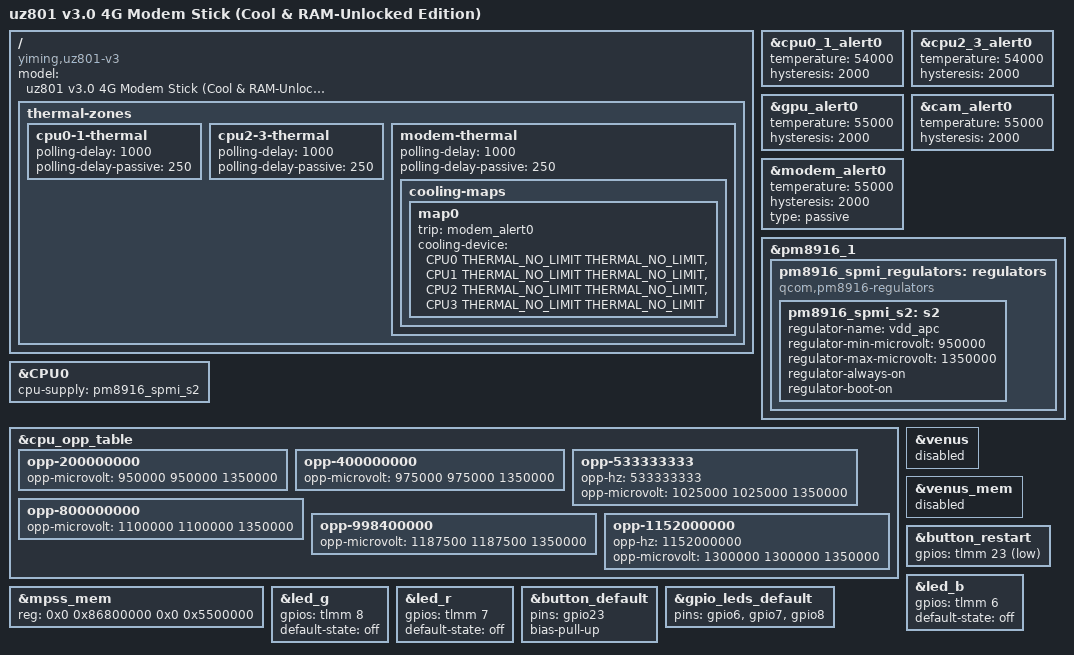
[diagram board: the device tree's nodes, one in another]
// SPDX-License-Identifier: GPL-2.0-only
/*
 * Custom Thermal-Tuned, RAM-Unlocked & OPP-Extended Device Tree
 * for Yiming UZ801 v3.0 (Qualcomm Snapdragon 410 / MSM8916)
 */

/dts-v1/;

#include "msm8916-ufi.dtsi"

/ {
	model = "uz801 v3.0 4G Modem Stick (Cool & RAM-Unlocked Edition)";
	compatible = "yiming,uz801-v3", "qcom,msm8916";

	thermal-zones {
		cpu0-1-thermal {
			polling-delay = <1000>;
			polling-delay-passive = <250>;
		};

		cpu2-3-thermal {
			polling-delay = <1000>;
			polling-delay-passive = <250>;
		};

		modem-thermal {
			polling-delay = <1000>;
			polling-delay-passive = <250>;

			cooling-maps {
				map0 {
					trip = <&modem_alert0>;
					cooling-device = <&CPU0 THERMAL_NO_LIMIT THERMAL_NO_LIMIT>,
							 <&CPU1 THERMAL_NO_LIMIT THERMAL_NO_LIMIT>,
							 <&CPU2 THERMAL_NO_LIMIT THERMAL_NO_LIMIT>,
							 <&CPU3 THERMAL_NO_LIMIT THERMAL_NO_LIMIT>;
				};
			};
		};
	};
};

/* Lower thermal throttling trip points from 75-85C down to 54C to keep chip < 60C */
&cpu0_1_alert0 {
	temperature = <54000>;
	hysteresis = <2000>;
};

&cpu2_3_alert0 {
	temperature = <54000>;
	hysteresis = <2000>;
};

&gpu_alert0 {
	temperature = <55000>;
	hysteresis = <2000>;
};

&cam_alert0 {
	temperature = <55000>;
	hysteresis = <2000>;
};

&modem_alert0 {
	temperature = <55000>;
	hysteresis = <2000>;
	type = "passive";
};

/* Enable PM8916 SPMI s2 buck regulator (vdd_apc) for Dynamic CPU Undervolting (0.95V - 1.325V) */
&pm8916_1 {
	pm8916_spmi_regulators: regulators {
		compatible = "qcom,pm8916-regulators";

		pm8916_spmi_s2: s2 {
			regulator-name = "vdd_apc";
			regulator-min-microvolt = <950000>;
			regulator-max-microvolt = <1350000>;
			regulator-always-on;
			regulator-boot-on;
		};
	};
};

&CPU0 {
	cpu-supply = <&pm8916_spmi_s2>;
};

/* Unlock 533 MHz sweet-spot cool frequency, 1.15 GHz Turbo Overclock, and SVS2 Deep Undervolt table */
&cpu_opp_table {
	opp-200000000 {
		opp-microvolt = <950000 950000 1350000>;
	};

	opp-400000000 {
		opp-microvolt = <975000 975000 1350000>;
	};

	opp-533333333 {
		opp-hz = /bits/ 64 <533333333>;
		opp-microvolt = <1025000 1025000 1350000>;
	};

	opp-800000000 {
		opp-microvolt = <1100000 1100000 1350000>;
	};

	opp-998400000 {
		opp-microvolt = <1187500 1187500 1350000>;
	};

	opp-1152000000 {
		opp-hz = /bits/ 64 <1152000000>;
		opp-microvolt = <1300000 1300000 1350000>;
	};
};

/* Keep MPSS carveout at 0x5500000 so WCNSS does not overlap MPSS internal heap */
&mpss_mem {
	reg = <0x0 0x86800000 0x0 0x5500000>;
	status = "okay";
};

/* Disable unused Venus H.264 video decoder/encoder hardware -> +5 MB RAM & lower heat */
&venus {
	status = "disabled";
};

&venus_mem {
	status = "disabled";
};

&button_restart {
	gpios = <&tlmm 23 GPIO_ACTIVE_LOW>;
};

/* Keep all LEDs off by default at boot to reduce PCB heat & glare */
&led_b {
	gpios = <&tlmm 6 GPIO_ACTIVE_HIGH>;
	default-state = "off";
};

&led_g {
	gpios = <&tlmm 8 GPIO_ACTIVE_HIGH>;
	default-state = "off";
};

&led_r {
	gpios = <&tlmm 7 GPIO_ACTIVE_HIGH>;
	default-state = "off";
};

&button_default {
	pins = "gpio23";
	bias-pull-up;
};

&gpio_leds_default {
	pins = "gpio6", "gpio7", "gpio8";
};
